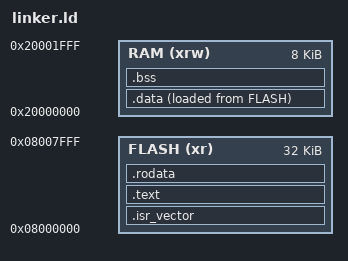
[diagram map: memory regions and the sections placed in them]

ENTRY(Reset_Handler)

_estack = ORIGIN(RAM) + LENGTH(RAM);

/* Memory definition */
MEMORY
{
  RAM (xrw)     : ORIGIN = 0x20000000, LENGTH = 8K
  FLASH (xr)    : ORIGIN = 0x08000000, LENGTH = 32K
}


/* Output Sections */
SECTIONS
{
  /* The startup code into "FLASH" Rom type memory */
  .isr_vector :
  {
    . = ALIGN(4);
    *(.isr_vector)
    . = ALIGN(4);
  } > FLASH

  /* The program code and other data into "FLASH" Rom type memory */
  .text :
  {
    . = ALIGN(4);
    *(.text)
    *(.text*)
    . = ALIGN(4);
    _etext = .;
  } > FLASH

  /* Constant data into "FLASH" Rom type memory */
  .rodata :
  {
    . = ALIGN(4);
    *(.rodata)    /* .rodata sections (constants, strings, etc.) */
    *(.rodata*)   /* .rodata* sections (constants, strings, etc.) */
    . = ALIGN(4);
  } > FLASH

  _sidata = LOADADDR(.data);

  .data :
  {
    . = ALIGN(4);
    _sdata = .;
    *(.data)
    *(.data*)
    . = ALIGN(4);
    _edata = .;
  } > RAM AT > FLASH

  .bss :
  {
    _sbss = .;
    *(.bss)
    *(.bss*)
    . = ALIGN(4);
    _ebss = .;
  } > RAM

}
